# H3 register map
Vendor: Allwinner; Series: H3; File version: 0.1
CPU: 0, little endian, MPU, no FPU, 0 interrupt priority bits
Registers are 32-bit, read-write, reset 0x0 unless marked. A register's access mark holds for its fields unless they carry their own. Offsets are from the block's base; [hi:lo] are bit positions; {n}, {i} and the like mark numbered series; 'fields as' and 'values as' point back to an identical list.

## CCU
Base 0x01C20000
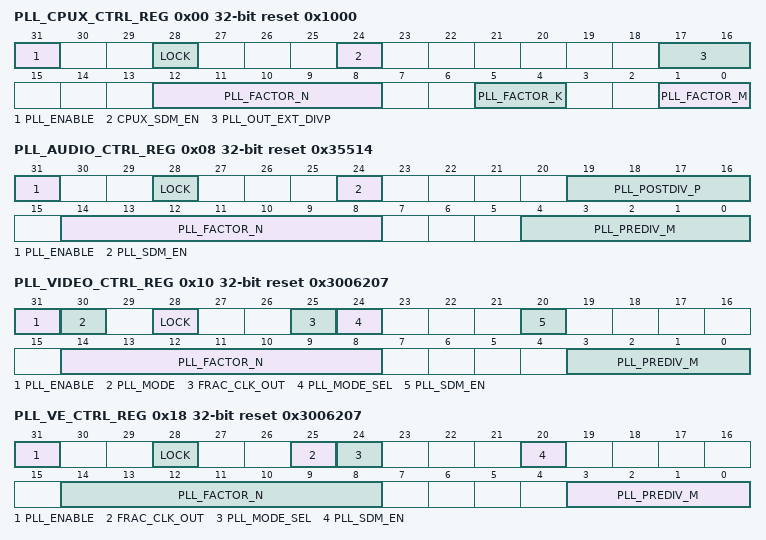
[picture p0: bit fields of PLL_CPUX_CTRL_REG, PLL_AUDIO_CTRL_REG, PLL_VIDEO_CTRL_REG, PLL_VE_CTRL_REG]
0x00 PLL_CPUX_CTRL_REG reset 0x1000 — PLL_CPUX Control Register
  [31] PLL_ENABLE — 0: Disable 1: Enable The PLL Output= (24MHz*N*K)/(M*P). The PLL output is for the CPUX Clock. Note: The PLL output clock must be in the range of 200MHz~2.6GHz. Its default is 408MHz.
    0=Disable; 1=Enable The PLL Output= (24MHz*N*K)/(M*P). The PLL output is for the CPUX Clock. Note: The PLL output clock must be in the range of 200MHz~2.6GHz. Its default is 408MHz.
  [28] LOCK ro — 0: Unlocked 1: Locked (It indicates that the PLL has been stable.)
    0=Unlocked; 1=Locked (It indicates that the PLL has been stable.)
  [24] CPUX_SDM_EN — 0: Disable 1: Enable
    0=Disable; 1=Enable
  [17:16] PLL_OUT_EXT_DIVP — PLL Output external divider P 00: /1 01: /2 10: /4 11: / Note:The P factor only use in the condition that PLL output less than 288 MHz.
    0=_slash_1 (/1); 1=_slash_2 (/2); 2=_slash_4 (/4); 3=_slash_ (/ Note:The P factor only use in the condition that PLL output less than 288 MHz.)
  [12:8] PLL_FACTOR_N — PLL Factor N. Factor=0, N=1 Factor=1, N=2 Factor=2, N=3 ... Factor=31, N=32
  [5:4] PLL_FACTOR_K — PLL Factor K.(K=Factor + 1 ) The range is from 1 to 4.
  [1:0] PLL_FACTOR_M — PLL Factor M. (M=Factor + 1) The range is from 1 to 4.
0x08 PLL_AUDIO_CTRL_REG reset 0x35514 — PLL_AUDIO Control Register
  [31] PLL_ENABLE — 0: Disable 1: Enable. The PLL is for Audio. PLL _AUDIO = (24MHz*N)/(M*P) PLL_AUDIO(8X)= (24MHz*N*2)/M PLL_AUDIO(4X)=PLL_AUDIO(8X)/2 PLL_AUDIO(2X)=PLL_AUDIO(4X)/2 The PLL output clock must be in the range of 20MHz~200MHz. Its default is 24.571MHz.
    0=Disable; 1=Enable. The PLL is for Audio. PLL _AUDIO = (24MHz*N)/(M*P) PLL_AUDIO(8X)= (24MHz*N*2)/M PLL_AUDIO(4X)=PLL_AUDIO(8X)/2 PLL_AUDIO(2X)=PLL_AUDIO(4X)/2 The PLL output clock must be in the range of 20MHz~200MHz. Its default is 24.571MHz.
  [28] LOCK ro — 0: Unlocked 1: Locked (It indicates that the PLL has been stable.)
    values as PLL_CPUX_CTRL_REG.LOCK
  [24] PLL_SDM_EN — 0: Disable 1: Enable In this case, the PLL_FACTOR_N only low 4 bits are valid (N: The range is from 1 to 16).
    0=Disable; 1=Enable In this case, the PLL_FACTOR_N only low 4 bits are valid (N: The range is from 1 to 16)
  [19:16] PLL_POSTDIV_P — Post-div factor (P= Factor+1) The range is from 1 to 16.
  [14:8] PLL_FACTOR_N — PLL Factor N. Factor=0, N=1 Factor=1, N=2 ... Factor=127, N=128
  [4:0] PLL_PREDIV_M — PLL Pre-div Factor(M = Factor+1). The range is from 1 to 32.
0x10 PLL_VIDEO_CTRL_REG reset 0x3006207 — PLL_VIDEO Control Register
  [31] PLL_ENABLE — 0: Disable 1: Enable In the integer mode,the PLL Output = (24MHz*N)/M. In the fractional mode, the PLL Output is select by bit 25. Note: In the Clock Control Module, PLL(1X) Output=PLL while PLL(2X) Output=PLL * 2. The PLL output clock must be in the range of 30MHz~600MHz. Its default is 297MHz.
    0=Disable; 1=Enable In the integer mode,the PLL Output = (24MHz*N)/M. In the fractional mode, the PLL Output is select by bit 25. Note: In the Clock Control Module, PLL(1X) Output=PLL while PLL(2X) Output=PLL * 2. The PLL output clock must be in the range of 30MHz~600MHz. Its default is 297MHz.
  [30] PLL_MODE — 0: Manual Mode 1: Auto Mode (Controlled by DE)
    0=Manual Mode; 1=Auto Mode (Controlled by DE)
  [28] LOCK ro — 0: Unlocked 1: Locked (It indicates that the PLL has been stable.)
    values as PLL_CPUX_CTRL_REG.LOCK
  [25] FRAC_CLK_OUT — PLL clock output when PLL_MODE_SEL=0(PLL_PREDIV_M factor must be set to 0); No meaning when PLL_MODE_SEL =1. 0: PLL Output=270MHz 1: PLL Output =297MHz
    0=PLL_Output_equals_270MHz (PLL Output=270MHz); 1=PLL Output =297MHz
  [24] PLL_MODE_SEL — 0: Fractional Mode 1: Integer Mode Note: When in Fractional mode, the Per Divider M should be set to 0.
    0=Fractional Mode; 1=Integer Mode Note: When in Fractional mode, the Per Divider M should be set to 0
  [20] PLL_SDM_EN — 0: Disable 1: Enable
    0=Disable; 1=Enable
  [14:8] PLL_FACTOR_N — PLL Factor N. Factor=0, N=1 Factor=1, N=2 Factor=2, N=3 ... Factor=127, N=128
  [3:0] PLL_PREDIV_M — PLL Pre-div Factor(M = Factor+1). The range is from 1 to 16.
0x18 PLL_VE_CTRL_REG reset 0x3006207 — PLL_VE Control Register
  [31] PLL_ENABLE — 0: Disable 1: Enable In the integer mode, The PLL Output = (24MHz*N)/M. In the fractional mode, the PLL Output is select by bit 25. Note: The PLL output clock must be in the range of 30MHz~600MHz. Its default is 297MHz.
    0=Disable; 1=Enable In the integer mode, The PLL Output = (24MHz*N)/M. In the fractional mode, the PLL Output is select by bit 25. Note: The PLL output clock must be in the range of 30MHz~600MHz. Its default is 297MHz.
  [28] LOCK ro — 0: Unlocked 1: Locked (It indicates that the PLL has been stable.)
    values as PLL_CPUX_CTRL_REG.LOCK
  [25] FRAC_CLK_OUT — PLL clock output when PLL_MODE_SEL=0(PLL_PREDIV_M factor must be set to 0); No meaning when PLL_MODE_SEL =1. 0: PLL Output=270MHz 1: PLL Output =297MHz
    values as PLL_VIDEO_CTRL_REG.FRAC_CLK_OUT
  [24] PLL_MODE_SEL — 0: Fractional Mode 1: Integer Mode Note: When in Fractional mode, the Per Divider M should be set to 0.
    values as PLL_VIDEO_CTRL_REG.PLL_MODE_SEL
  [20] PLL_SDM_EN — 0: Disable 1: Enable
    0=Disable; 1=Enable
  [14:8] PLL_FACTOR_N — PLL Factor N. Factor=0, N=1 Factor=1, N=2 Factor=2, N=3 ... Factor=31, N=32 ... Factor=127, N=128
  [3:0] PLL_PREDIV_M — PLL Pre Divider (M = Factor+1). The range is from 1 to 16.
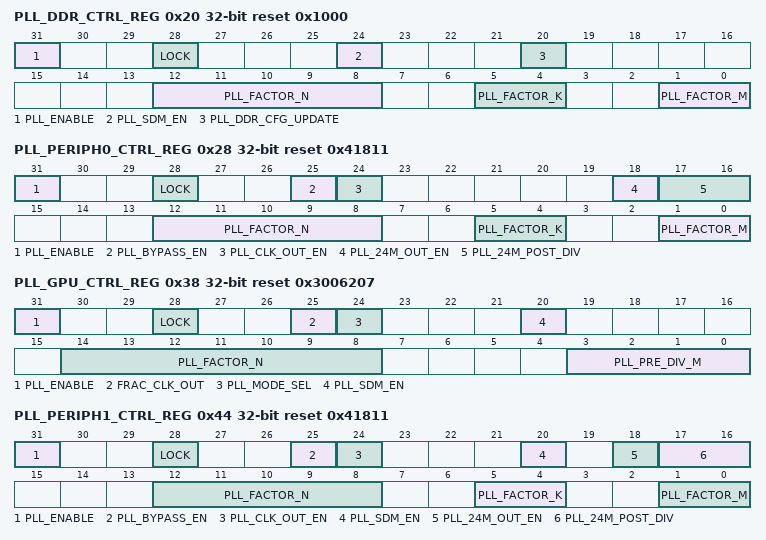
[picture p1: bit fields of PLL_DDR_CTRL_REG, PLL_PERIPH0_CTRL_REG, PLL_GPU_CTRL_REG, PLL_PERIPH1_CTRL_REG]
0x20 PLL_DDR_CTRL_REG reset 0x1000 — PLL_DDR Control Register
  [31] PLL_ENABLE — 0: Disable 1: Enable Set bit20 to validate the PLL after this bit is set to 1. The PLL Output = (24MHz*N*K)/M. Note: the PLL output clock must be in the range of 200MHz~2.6GHz. Its default is 408MHz.
    0=Disable; 1=Enable Set bit20 to validate the PLL after this bit is set to 1. The PLL Output = (24MHz*N*K)/M. Note: the PLL output clock must be in the range of 200MHz~2.6GHz. Its default is 408MHz.
  [28] LOCK ro — 0: Unlocked 1: Locked (It indicates that the PLL has been stable.)
    values as PLL_CPUX_CTRL_REG.LOCK
  [24] PLL_SDM_EN — 0: Disable 1: Enable
    0=Disable; 1=Enable
  [20] PLL_DDR_CFG_UPDATE — PLL_DDR Configuration Update. When PLL_DDR has been changed, this bit should be set to 1 to validate the PLL, otherwise the change would be invalid. And this bit would be cleared automatically after the PLL change is valid. 0: No effect 1: Validating the PLL_DDR
    0=No_effect; 1=Validating the PLL_DDR
  [12:8] PLL_FACTOR_N — PLL Factor N. Factor=0, N=1 Factor=1, N=2 Factor=2, N=3 ... Factor=31, N=32
  [5:4] PLL_FACTOR_K — PLL Factor K.(K=Factor + 1 ) The range is from 1 to 4.
  [1:0] PLL_FACTOR_M — PLL Factor M.(M = Factor + 1 ) The range is from 1 to 4.
0x28 PLL_PERIPH0_CTRL_REG reset 0x41811 — PLL_PERIPH0 Control Register
  [31] PLL_ENABLE — 0: Disable 1: Enable The PLL Output = 24MHz*N*K/2. Note: The PLL Output should be fixed to 600MHz, it is not recommended to vary this value arbitrarily. In the Clock Control Module, PLL(2X) output= PLL*2 = 24MHz*N*K. The PLL output clock must be in the range of 200MHz~1.8GHz. Its default is 600MHz.
    0=Disable; 1=Enable The PLL Output = 24MHz*N*K/2. Note: The PLL Output should be fixed to 600MHz, it is not recommended to vary this value arbitrarily. In the Clock Control Module, PLL(2X) output= PLL*2 = 24MHz*N*K. The PLL output clock must be in the range of 200MHz~1.8GHz. Its default is 600MHz.
  [28] LOCK ro — 0: Unlocked 1: Locked (It indicates that the PLL has been stable.)
    values as PLL_CPUX_CTRL_REG.LOCK
  [25] PLL_BYPASS_EN — PLL Output Bypass Enable. 0: Disable 1: Enable If the bypass is enabled, the PLL output is 24MHz.
    0=Disable; 1=Enable If the bypass is enabled, the PLL output is 24MHz
  [24] PLL_CLK_OUT_EN — PLL clock output enable. 0: Disable 1: Enable
    0=Disable; 1=Enable
  [18] PLL_24M_OUT_EN — PLL 24MHz Output Enable. 0: Disable 1: Enable When 25MHz crystal used, this PLL can output 24MHz.
    0=Disable; 1=Enable When 25MHz crystal used, this PLL can output 24MHz
  [17:16] PLL_24M_POST_DIV — PLL 24M Output Clock Post Divider (When 25MHz crystal used). 1/2/3/4.
  [12:8] PLL_FACTOR_N — PLL Factor N. Factor=0, N=1 Factor=1, N=2 Factor=2, N=3 ... Factor=31, N=32
  [5:4] PLL_FACTOR_K — PLL Factor K.(K=Factor + 1 ) The range is from 1 to 4.
  [1:0] PLL_FACTOR_M — PLL Factor M (M = Factor + 1) is only valid in plltest debug. The PLL_PERIPH back door clock output =24MHz*N*K/M. The range is from 1 to 4.
0x38 PLL_GPU_CTRL_REG reset 0x3006207 — PLL_GPU Control Register
  [31] PLL_ENABLE — 0: Disable 1: Enable In the integer mode, The PLL_GPU Output= (24MHz*N)/M. In the fractional mode, the PLL_GPU Output is select by bit 25. Note: The PLL output clock must be in the range of 30MHz~600MHz. Its default is 297MHz.
    0=Disable; 1=Enable In the integer mode, The PLL_GPU Output= (24MHz*N)/M. In the fractional mode, the PLL_GPU Output is select by bit 25. Note: The PLL output clock must be in the range of 30MHz~600MHz. Its default is 297MHz.
  [28] LOCK ro — 0: Unlocked 1: Locked (It indicates that the PLL has been stable.)
    values as PLL_CPUX_CTRL_REG.LOCK
  [25] FRAC_CLK_OUT — PLL clock output when PLL_MODE_SEL=0(PLL_PREDIV_M factor must be set to 0); no meaning when PLL_MODE_SEL =1. 0: PLL Output=270MHz 1: PLL Output=297MHz
    0=PLL_Output_equals_270MHz (PLL Output=270MHz); 1=PLL_Output_equals_297MHz (PLL Output=297MHz)
  [24] PLL_MODE_SEL — 0: Fractional Mode. 1: Integer Mode Note: When in Fractional mode, the Per Divider M should be set to 0.
    values as PLL_VIDEO_CTRL_REG.PLL_MODE_SEL
  [20] PLL_SDM_EN — 0: Disable 1: Enable
    0=Disable; 1=Enable
  [14:8] PLL_FACTOR_N — PLL Factor N. Factor=0, N=1 Factor=1, N=2 Factor=2, N=3 ... Factor=127, N=128
  [3:0] PLL_PRE_DIV_M — PLL Pre Divider (M = Factor+1). The range is from 1 to 16.
0x44 PLL_PERIPH1_CTRL_REG reset 0x41811
  [31] PLL_ENABLE — 0: Disable 1: Enable The PLL Output = 24MHz*N*K/2. Note: The PLL Output should be fixed to 600MHz, it is not recommended to vary this value arbitrarily. In the Clock Control Module, PLL(2X) output= PLL*2 = 24MHz*N*K. The PLL output clock must be in the range of 200MHz~1.8GHz. Its default is 600MHz.
    values as PLL_PERIPH0_CTRL_REG.PLL_ENABLE
  [28] LOCK ro — 0: Unlocked 1: Locked (It indicates that the PLL has been stable.)
    values as PLL_CPUX_CTRL_REG.LOCK
  [25] PLL_BYPASS_EN — PLL Output Bypass Enable. 0: Disable 1: Enable If the bypass is enabled, the PLL output is 24MHz.
    values as PLL_PERIPH0_CTRL_REG.PLL_BYPASS_EN
  [24] PLL_CLK_OUT_EN — PLL clock output enable. 0: Disable 1: Enable
    0=Disable; 1=Enable
  [20] PLL_SDM_EN — 0: Disable 1: Enable
    0=Disable; 1=Enable
  [18] PLL_24M_OUT_EN — PLL 24MHz Output Enable. 0: Disable 1: Enable When 25MHz crystal used, this PLL can output 24MHz.
    values as PLL_PERIPH0_CTRL_REG.PLL_24M_OUT_EN
  [17:16] PLL_24M_POST_DIV — PLL 24M Output Clock Post Divider (When 25MHz crystal used). 1/2/3/4.
  [12:8] PLL_FACTOR_N — PLL Factor N. Factor=0, N=1 Factor=1, N=2 Factor=2, N=3 ... Factor=31, N=32
  [5:4] PLL_FACTOR_K — PLL Factor K.(K=Factor + 1 ) The range is from 1 to 4.
  [1:0] PLL_FACTOR_M — PLL Factor M (M = Factor + 1) is only valid in plltest debug. The PLL_PERIPH back door clock output =24MHz*N*K/M. The range is from 1 to 4.
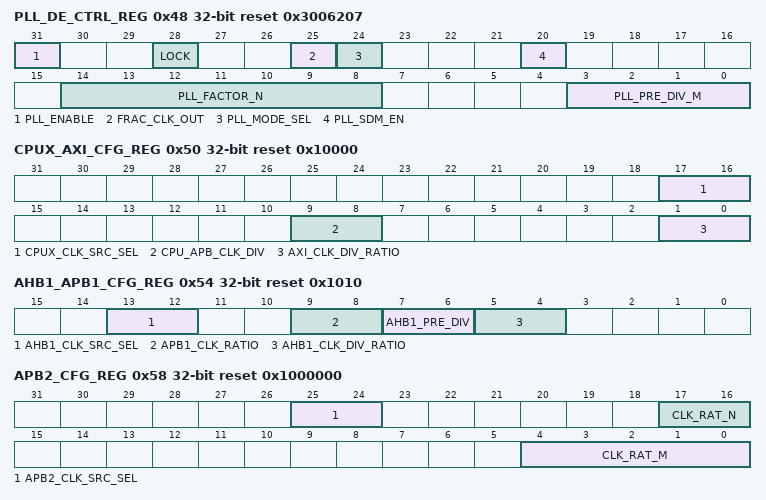
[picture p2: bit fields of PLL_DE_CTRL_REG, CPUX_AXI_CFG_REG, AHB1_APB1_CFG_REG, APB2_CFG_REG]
0x48 PLL_DE_CTRL_REG reset 0x3006207 — PLL_DE Control Register
  [31] PLL_ENABLE — 0: Disable 1: Enable In the integer mode, The PLL Output= (24MHz*N)/M. In the fractional mode, the PLL Output is select by bit 25. Its default is 297MHz.
    0=Disable; 1=Enable In the integer mode, The PLL Output= (24MHz*N)/M. In the fractional mode, the PLL Output is select by bit 25. Its default is 297MHz.
  [28] LOCK ro — 0: Unlocked 1: Locked (It indicates that the PLL has been stable.)
    values as PLL_CPUX_CTRL_REG.LOCK
  [25] FRAC_CLK_OUT — PLL clock output when PLL_MODE_SEL=0(PLL_PREDIV_M factor must be set to 0); no meaning when PLL_MODE_SEL =1. 0: PLL Output=270MHz 1: PLL Output =297MHz
    values as PLL_VIDEO_CTRL_REG.FRAC_CLK_OUT
  [24] PLL_MODE_SEL — 0: Fractional Mode 1: Integer Mode Note: When in Fractional mode, the Pre Divider M should be set to 0.
    0=Fractional Mode; 1=Integer Mode Note: When in Fractional mode, the Pre Divider M should be set to 0
  [20] PLL_SDM_EN — 0: Disable 1: Enable
    0=Disable; 1=Enable
  [14:8] PLL_FACTOR_N — PLL Factor N. Factor=0, N=1 Factor=1, N=2 Factor=2, N=3 ... Factor=0x7F, N=128
  [3:0] PLL_PRE_DIV_M — PLL Per Divider (M = Factor+1). The range is from 1 to 16.
0x50 CPUX_AXI_CFG_REG reset 0x10000 — CPUX/AXI Configuration Register
  [17:16] CPUX_CLK_SRC_SEL — CPUX Clock Source Select. CPUX Clock = Clock Source 00: LOSC 01: OSC24M 1X: PLL_CPUX If the clock source is changed, at most to wait for 8 present running clock cycles.
    0=LOSC; 1=OSC24M; 2=PLL_CPUX (PLL_CPUX If the clock source is changed, at most to wait for 8 present running clock cycles.)
  [9:8] CPU_APB_CLK_DIV — 00: /1 01: /2 1x: /4 Note: System APB clock source is CPU clock source.
    0=_slash_1 (/1); 1=_slash_2 (/2); 2=_slash_4 (/4 Note: System APB clock source is CPU clock source.)
  [1:0] AXI_CLK_DIV_RATIO — AXI Clock Divide Ratio. AXI Clock source is CPU clock source. 00: /1 01: /2 10: /3 11: /4
    {v}=_slash_{v+1} (/{v+1}) (v=0..3)
0x54 AHB1_APB1_CFG_REG reset 0x1010 — AHB1/APB1 Configuration Register
  [13:12] AHB1_CLK_SRC_SEL — 00: LOSC 01: OSC24M 10: AXI 11: PLL_PERIPH0/ AHB1_PRE_DIV
    0=LOSC; 1=OSC24M; 2=AXI; 3=PLL_PERIPH0_slash_ (PLL_PERIPH0/ AHB1_PRE_DIV)
  [9:8] APB1_CLK_RATIO — APB1 Clock Divide Ratio. APB1 clock source is AHB1 clock. 00: /2 01: /2 10: /4 11: /8
  [7:6] AHB1_PRE_DIV — AHB1 Clock Pre Divide Ratio 00: /1 01: /2 10: /3 11: /4
    {v}=_slash_{v+1} (/{v+1}) (v=0..3)
  [5:4] AHB1_CLK_DIV_RATIO — AHB1 Clock Divide Ratio. 00: /1 01: /2 10: /4 11: /8
    0=_slash_1 (/1); 1=_slash_2 (/2); 2=_slash_4 (/4); 3=_slash_8 (/8)
0x58 APB2_CFG_REG reset 0x1000000
  [25:24] APB2_CLK_SRC_SEL — APB2 Clock Source Select 00: LOSC 01: OSC24M 1X: PLL_PERIPH0 This clock is used for some special module apbclk(UART TWI). Because these modules need special clock rate even if the apb1clk changed.
    0=LOSC; 1=OSC24M; 2=PLL_PERIPH0 (PLL_PERIPH0 This clock is used for some special module apbclk(UART TWI). Because these modules need special clock rate even if the apb1clk changed.)
  [17:16] CLK_RAT_N — Clock Pre Divide Ratio (n) The select clock source is pre-divided by 2^n. The divider is 1/2/4/8.
  [4:0] CLK_RAT_M — Clock Divide Ratio (m) The Pre Divide clock is divided by (m+1). The divider M is from 1 to 32.
0x5C AHB2_CFG_REG — AHB2 Configuration Register
  [1:0] AHB2_CLK_CFG — 00: AHB1 Clock 01: PLL_PERIPH0 / 2 1X: / EMAC ,USBHCI1/2/3 default clock source is AHB2 Clock.
    0=AHB1 (AHB1 Clock); 1=PLL_PERIPH0 (PLL_PERIPH0 / 2); 2=_slash_ (/ EMAC ,USBHCI1/2/3 default clock source is AHB2 Clock.)
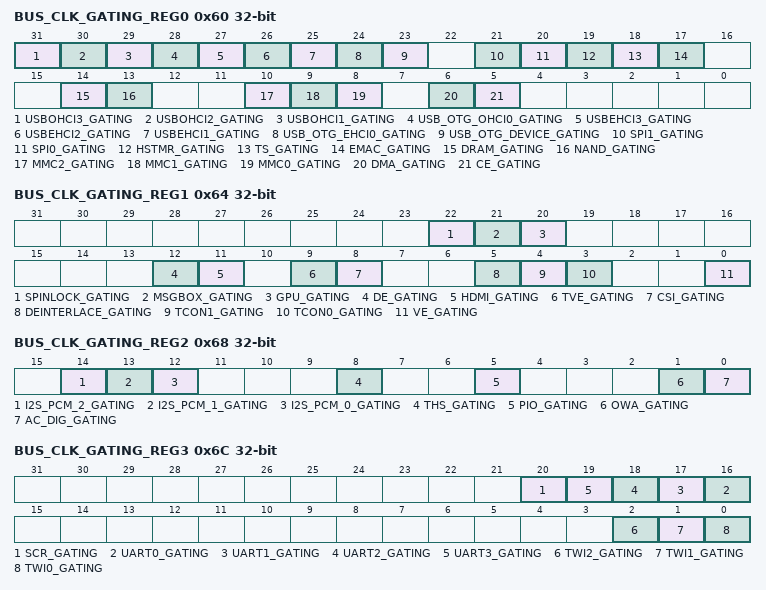
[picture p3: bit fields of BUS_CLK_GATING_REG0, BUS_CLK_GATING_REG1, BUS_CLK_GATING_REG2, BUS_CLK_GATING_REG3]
0x60 BUS_CLK_GATING_REG0 — Bus Clock Gating Register 0
  [all] fields
    0=Mask; 1=Pass
  [31] USBOHCI3_GATING — USBOHCI3_GATING. Gating Clock for USB OHCI3 0: Mask 1: Pass
  [30] USBOHCI2_GATING — USBOHCI2_GATING. Gating Clock for USB OHCI2 0: Mask 1: Pass
  [29] USBOHCI1_GATING — USBOHCI1_GATING. Gating Clock for USB OHCI1 0: Mask 1: Pass
  [28] USB_OTG_OHCI0_GATING — USB OTG_OHCI0_GATING. Gating Clock for USB OTG_OHCI0 0: Mask 1: Pass
  [27] USBEHCI3_GATING — USBEHCI3_GATING. Gating Clock For USB EHCI3 0: Mask 1: Pass
  [26] USBEHCI2_GATING — USBEHCI2_GATING. Gating Clock For USB EHCI2 0: Mask 1: Pass
  [25] USBEHCI1_GATING — USBEHCI1_GATING. Gating Clock For USB EHCI1 0: Mask 1: Pass
  [24] USB_OTG_EHCI0_GATING — USB OTG_EHCI0_GATING. Gating Clock For USB OTG_EHCI0 0: Mask 1: Pass
  [23] USB_OTG_DEVICE_GATING — USB OTG_Device_GATING. Gating Clock For USB OTG_Device 0: Mask 1: Pass
  [21] SPI1_GATING — SPI1_GATING. Gating Clock For SPI1 0: Mask 1: Pass
  [20] SPI0_GATING — SPI0_GATING. Gating Clock For SPI0 0: Mask 1: Pass
  [19] HSTMR_GATING — HSTMR_GATING. Gating Clock For High Speed Timer 0: Mask 1: Pass
  [18] TS_GATING — TS_GATING. Gating Clock For TS 0: Mask 1: Pass
  [17] EMAC_GATING — EMAC_GATING. Gating Clock For EMAC 0: Mask 1: Pass
  [14] DRAM_GATING — DRAM_GATING. Gating Clock For DRAM 0: Mask 1: Pass
  [13] NAND_GATING — NAND_GATING. Gating Clock For NAND 0: Mask 1: Pass
  [10] MMC2_GATING — MMC2_GATING. Gating Clock For MMC2 0: Mask 1: Pass
  [9] MMC1_GATING — MMC1_GATING. Gating Clock For MMC1 0: Mask 1: Pass
  [8] MMC0_GATING — MMC0_GATING. Gating Clock For MMC0 0: Mask 1: Pass
  [6] DMA_GATING — DMA_GATING. Gating Clock For DMA 0: Mask 1: Pass
  [5] CE_GATING — CE_GATING. Gating Clock For CE. 0: Mask 1: Pass
0x64 BUS_CLK_GATING_REG1 — Bus Clock Gating Register 1
  [all] fields
    0=Mask; 1=Pass
  [22] SPINLOCK_GATING — 0: Mask 1: Pass.
  [21] MSGBOX_GATING — 0: Mask 1: Pass.
  [20] GPU_GATING — 0: Mask 1: Pass.
  [12] DE_GATING — 0: Mask 1: Pass.
  [11] HDMI_GATING — 0: Mask 1: Pass.
  [9] TVE_GATING — Gating Clock For TVE 0: Mask 1: Pass.
  [8] CSI_GATING — 0: Mask 1: Pass.
  [5] DEINTERLACE_GATING — Gating Clock For DEINTERLACE 0: Mask 1: Pass
  [4] TCON1_GATING — Gating Clock For TCON1 0: Mask 1: Pass.
  [3] TCON0_GATING — Gating Clock For TCON0 0: Mask 1: Pass.
  [0] VE_GATING — Gating Clock For VE 0: Mask 1: Pass.
0x68 BUS_CLK_GATING_REG2 — Bus Clock Gating Register 2
  [all] fields
    0=Mask; 1=Pass
  [14] I2S_PCM_2_GATING — Gating Clock For I2S/PCM 2 0: Mask 1: Pass.
  [13] I2S_PCM_1_GATING — Gating Clock For I2S/PCM 1 0: Mask 1: Pass.
  [12] I2S_PCM_0_GATING — Gating Clock For I2S/PCM 0 0: Mask 1: Pass.
  [8] THS_GATING — Gating Clock For THS 0: Mask 1: Pass
  [5] PIO_GATING — Gating Clock For PIO 0: Mask 1: Pass.
  [1] OWA_GATING — Gating Clock For OWA 0: Mask 1: Pass.
  [0] AC_DIG_GATING — Gating Clock For AC Digital 0: Mask 1: Pass
0x6C BUS_CLK_GATING_REG3 — Bus Clock Gating Register 3
  [all] fields
    0=Mask; 1=Pass
  [20] SCR_GATING — Gating Clock For SCR 0: Mask 1: Pass
  [n+16] UART{n}_GATING (n=0..3) — Gating Clock For UART{n} 0: Mask 1: Pass.
  [2] TWI2_GATING — Gating Clock For TWI2 0: Mask 1: Pass.
  [1] TWI1_GATING — Gating Clock For TWI1 0: Mask 1: Pass.
  [0] TWI0_GATING — Gating Clock For TWI0 0: Mask 1: Pass.
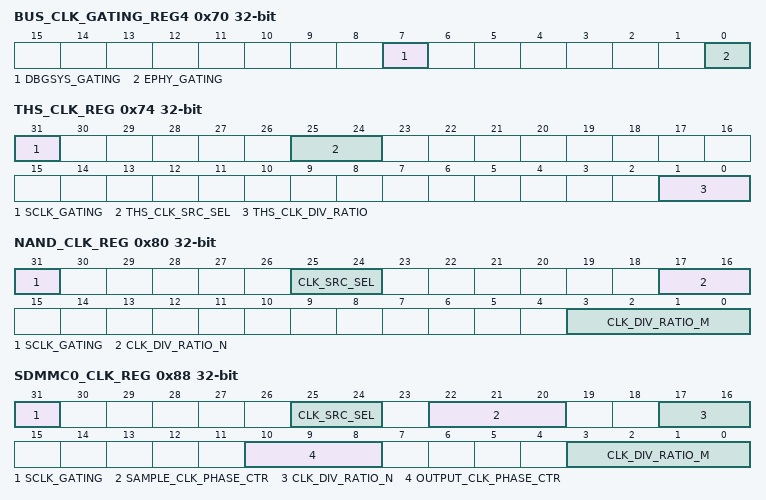
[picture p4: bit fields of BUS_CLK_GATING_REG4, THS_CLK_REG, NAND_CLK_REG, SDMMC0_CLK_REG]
0x70 BUS_CLK_GATING_REG4 — Bus Clock Gating Register4
  [7] DBGSYS_GATING — Gating Clock For DBGSYS 0: Mask 1: Pass
    0=Mask; 1=Pass
  [0] EPHY_GATING — Gating Clock For EPHY 0: Mask 1: Pass
    0=Mask; 1=Pass
0x74 THS_CLK_REG — THS Clock Register
  [31] SCLK_GATING — Gating Special Clock. 0: Clock is OFF 1: Clock is ON This special clock = Clock Source/CLK_DIV_RATIO.
    0=OFF (Clock is OFF); 1=ON (Clock is ON This special clock = Clock Source/CLK_DIV_RATIO.)
  [25:24] THS_CLK_SRC_SEL — Clock Source Select 00: OSC24M 01: / 10: / 11: /
    0=OSC24M
  [1:0] THS_CLK_DIV_RATIO — THS clock divide ratio. 00: /1 01: /2 10: /4 11: /6
    0=_slash_1 (/1); 1=_slash_2 (/2); 2=_slash_4 (/4); 3=_slash_6 (/6)
0x80 NAND_CLK_REG — NAND Clock Register
  [31] SCLK_GATING — Gating Special Clock(Max Clock = 200MHz) 0: Clock is OFF 1: Clock is ON. SCLK = Clock Source/Divider N/Divider M.
    0=OFF (Clock is OFF); 1=ON (Clock is ON. SCLK = Clock Source/Divider N/Divider M.)
  [25:24] CLK_SRC_SEL — Clock Source Select 00: OSC24M 01: PLL_PERIPH0 10: PLL_PERIPH1 11: /
    0=OSC24M; 1=PLL_PERIPH0; 2=PLL_PERIPH1
  [17:16] CLK_DIV_RATIO_N — Clock Pre Divide Ratio (n) 00: /1 01: /2 10: /4 11: /8.
    0=_slash_1 (/1); 1=_slash_2 (/2); 2=_slash_4 (/4); 3=_slash_8 (/8.)
  [3:0] CLK_DIV_RATIO_M — Clock Divide Ratio (m) The pre-divided clock is divided by (m+1). The divider M is from 1 to 16.
0x88 SDMMC0_CLK_REG — SDMMC0 Clock Register
  [31] SCLK_GATING — Gating Special Clock(Max Clock = 200MHz) 0: Clock is OFF 1: Clock is ON. SCLK = Clock Source/Divider N/Divider M.
    values as NAND_CLK_REG.SCLK_GATING
  [25:24] CLK_SRC_SEL — Clock Source Select 00: OSC24M 01: PLL_PERIPH0 10: PLL_PERIPH1 11: /
    0=OSC24M; 1=PLL_PERIPH0; 2=PLL_PERIPH1
  [22:20] SAMPLE_CLK_PHASE_CTR — Sample Clock Phase Control. The sample clock phase delay is based on the number of source clock that is from 0 to 7.
  [17:16] CLK_DIV_RATIO_N — Clock Pre Divide Ratio (n) 00: /1 01: /2 10: /4 11: /8.
    values as NAND_CLK_REG.CLK_DIV_RATIO_N
  [10:8] OUTPUT_CLK_PHASE_CTR — Output Clock Phase Control. The output clock phase delay is based on the number of source clock that is from 0 to 7.
  [3:0] CLK_DIV_RATIO_M — Clock Divide Ratio (m) The pre-divided clock is divided by (m+1). The divider M is from 1 to 16.
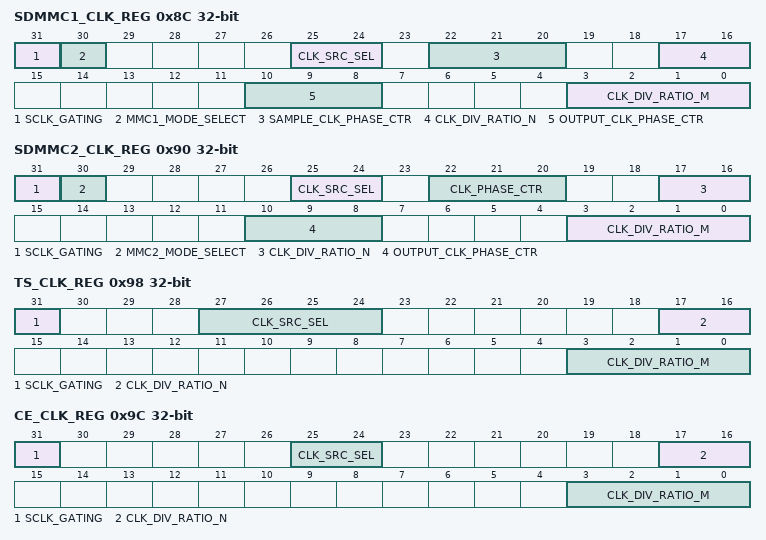
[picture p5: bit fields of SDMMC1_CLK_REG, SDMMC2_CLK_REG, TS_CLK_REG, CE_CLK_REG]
0x8C SDMMC1_CLK_REG — SDMMC1 Clock Register
  [31] SCLK_GATING — Gating Special Clock(Max Clock = 200MHz) 0: Clock is OFF 1: Clock is ON. If SDMMC1 is in old mode, SCLK = Clock Source/Divider N/Divider M. If SDMMC1 is in new mode, SCLK= Clock Source/Divider N/Divider M/2.
    0=OFF (Clock is OFF); 1=ON (Clock is ON. If SDMMC1 is in old mode, SCLK = Clock Source/Divider N/Divider M. If SDMMC1 is in new mode, SCLK= Clock Source/Divider N/Divider M/2.)
  [30] MMC1_MODE_SELECT — 0: Old Mode 1: New Mode.
    0=Old (Old Mode); 1=New (New Mode.)
  [25:24] CLK_SRC_SEL — Clock Source Select 00: OSC24M 01: PLL_PERIPH0 10: PLL_PERIPH1 11: /
    0=OSC24M; 1=PLL_PERIPH0; 2=PLL_PERIPH1
  [22:20] SAMPLE_CLK_PHASE_CTR — Sample Clock Phase Control. The sample clock phase delay is based on the number of source clock that is from 0 to 7.
  [17:16] CLK_DIV_RATIO_N — Clock Pre-Divide Ratio (n) 00: /1 01: /2 10: /4 11: /8.
    values as NAND_CLK_REG.CLK_DIV_RATIO_N
  [10:8] OUTPUT_CLK_PHASE_CTR — Output Clock Phase Control. The output clock phase delay is based on the number of source clock that is from 0 to 7.
  [3:0] CLK_DIV_RATIO_M — Clock Divide Ratio (m) The pre-divided clock is divided by (m+1). The divider M is from 1 to 16.
0x90 SDMMC2_CLK_REG — SDMMC2 Clock Register
  [31] SCLK_GATING — Gating Special Clock(Max Clock = 200MHz) 0: Clock is OFF 1: Clock is ON. If SDMMC2 is in old mode, SCLK = Clock Source/Divider N/Divider M. If SDMMC2 is in new mode, SCLK= Clock Source/Divider N/Divider M/2.
    0=OFF (Clock is OFF); 1=ON (Clock is ON. If SDMMC2 is in old mode, SCLK = Clock Source/Divider N/Divider M. If SDMMC2 is in new mode, SCLK= Clock Source/Divider N/Divider M/2.)
  [30] MMC2_MODE_SELECT — 0: Old Mode 1: New Mode.
    0=Old (Old Mode); 1=New (New Mode.)
  [25:24] CLK_SRC_SEL — Clock Source Select 00: OSC24M 01: PLL_PERIPH0 10: PLL_PERIPH1 11: /
    0=OSC24M; 1=PLL_PERIPH0; 2=PLL_PERIPH1
  [22:20] CLK_PHASE_CTR — Sample Clock Phase Control. The sample clock phase delay is based on the number of source clock that is from 0 to 7.
  [17:16] CLK_DIV_RATIO_N — Clock Pre Divide Ratio (n) 00: /1 01: /2 10: /4 11: /8.
    values as NAND_CLK_REG.CLK_DIV_RATIO_N
  [10:8] OUTPUT_CLK_PHASE_CTR — Output Clock Phase Control. The output clock phase delay is based on the number of source clock that is from 0 to 7.
  [3:0] CLK_DIV_RATIO_M — Clock Divide Ratio (m) The pre-divided clock is divided by (m+1). The divider M is from 1 to 16.
0x98 TS_CLK_REG
  [31] SCLK_GATING — Gating Special Clock(Max Clock = 200MHz) 0: Clock is OFF 1: Clock is ON. SCLK = Clock Source/Divider N/Divider M.
    values as NAND_CLK_REG.SCLK_GATING
  [27:24] CLK_SRC_SEL — Clock Source Select 0000: OSC24M 0001: PLL_PERIPH0 Others: /
    0=OSC24M; 1=PLL_PERIPH0 (PLL_PERIPH0 Others: /)
  [17:16] CLK_DIV_RATIO_N — Clock pre-divide ratio (n) The select clock source is pre-divided by 2^n. The divider is 1/2/4/8.
  [3:0] CLK_DIV_RATIO_M — Clock divide ratio (m) The pre-divided clock is divided by (m+1). The divider is from 1 to 16.
0x9C CE_CLK_REG — CE Clock Register
  [31] SCLK_GATING — Gating Special Clock(Max Clock = 400MHz) 0: Clock is OFF 1: Clock is ON. SCLK = Clock Source/Divider N/Divider M.
    values as NAND_CLK_REG.SCLK_GATING
  [25:24] CLK_SRC_SEL — Clock Source Select 00: OSC24M 01: PLL_PERIPH0 10: PLL_PERIPH1 11: /
    0=OSC24M; 1=PLL_PERIPH0; 2=PLL_PERIPH1
  [17:16] CLK_DIV_RATIO_N — Clock Pre Divide Ratio (n) 00: /1 01: /2 10: /4 11: /8.
    values as NAND_CLK_REG.CLK_DIV_RATIO_N
  [3:0] CLK_DIV_RATIO_M — Clock divide ratio (m) The pre-divided clock is divided by (m+1). The divider M is from 1 to 16.
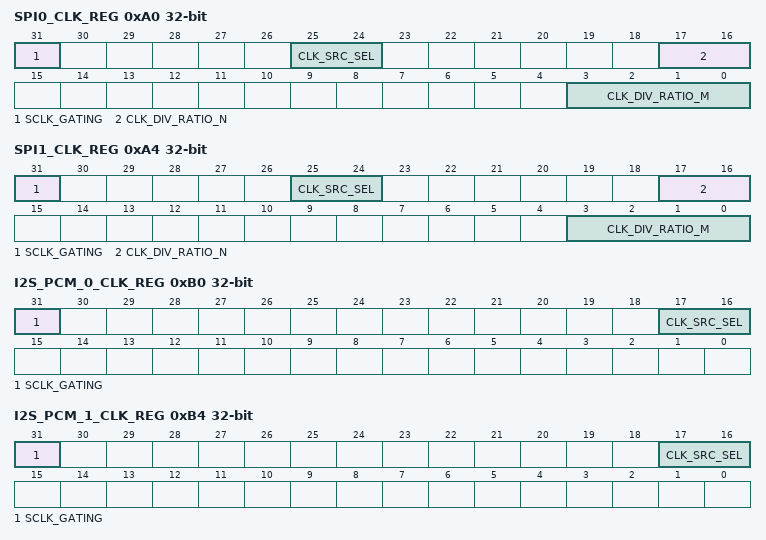
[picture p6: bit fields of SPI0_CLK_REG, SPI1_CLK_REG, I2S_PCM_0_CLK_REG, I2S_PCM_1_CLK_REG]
0xA0 SPI0_CLK_REG — SPI0 Clock Register
  fields as NAND_CLK_REG
0xA4 SPI1_CLK_REG — SPI1 Clock Register
  [31] SCLK_GATING — Gating Special Clock(Max Clock = 200MHz) 0: Clock is OFF 1: Clock is ON. SCLK= Clock Source/Divider N/Divider M.
    0=OFF (Clock is OFF); 1=ON (Clock is ON. SCLK= Clock Source/Divider N/Divider M.)
  [25:24] CLK_SRC_SEL — Clock Source Select 00: OSC24M 01: PLL_PERIPH0 10: PLL_PERIPH1 11: /
    0=OSC24M; 1=PLL_PERIPH0; 2=PLL_PERIPH1
  [17:16] CLK_DIV_RATIO_N — Clock Pre Divide Ratio (n) 00: /1 01: /2 10: /4 11: /8.
    values as NAND_CLK_REG.CLK_DIV_RATIO_N
  [3:0] CLK_DIV_RATIO_M — Clock Divide Ratio (m) The pre-divided clock is divided by (m+1). The divider M is from 1 to 16.
0xB0 I2S_PCM_0_CLK_REG
  [31] SCLK_GATING — Gating Special Clock(Max Clock = 200MHz) 0: Clock is OFF 1: Clock is ON. SCLK= Clock Source PLL_AUDIO/Divider M.
    0=OFF (Clock is OFF); 1=ON (Clock is ON. SCLK= Clock Source PLL_AUDIO/Divider M.)
  [17:16] CLK_SRC_SEL — 00: PLL_AUDIO(8X) 01: PLL_AUDIO(8X)/2 10: PLL_AUDIO(8X)/4 11: PLL_AUDIO
    0=PLL_AUDIO_openingparen_8X_closingparen_ (PLL_AUDIO(8X)); 1=PLL_AUDIO_openingparen_8X_closingparen__slash_2 (PLL_AUDIO(8X)/2); 2=PLL_AUDIO_openingparen_8X_closingparen__slash_4 (PLL_AUDIO(8X)/4); 3=PLL_AUDIO
0xB4 I2S_PCM_1_CLK_REG
  [31] SCLK_GATING — Gating Special Clock(Max Clock = 200MHz) 0: Clock is OFF 1: Clock is ON.
    0=OFF (Clock is OFF); 1=ON (Clock is ON.)
  [17:16] CLK_SRC_SEL — 00: PLL_AUDIO (8X) 01: PLL_AUDIO(8X)/2 10: PLL_AUDIO(8X)/4 11: PLL_AUDIO
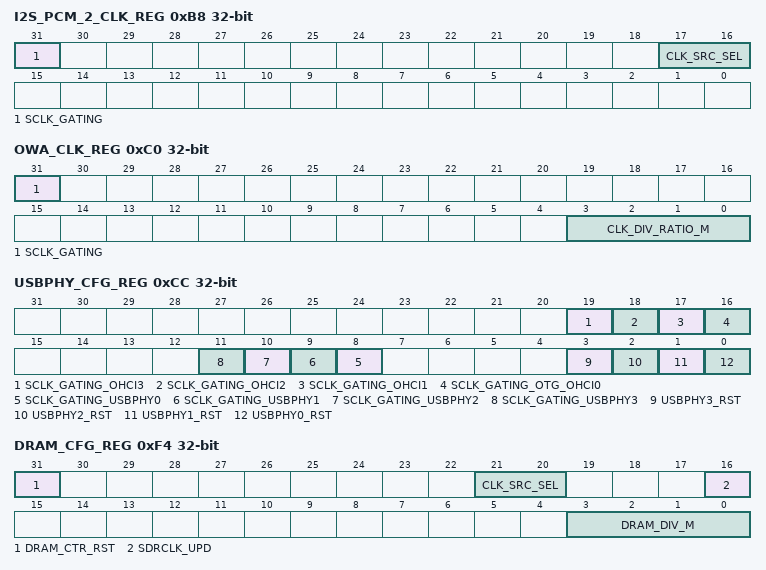
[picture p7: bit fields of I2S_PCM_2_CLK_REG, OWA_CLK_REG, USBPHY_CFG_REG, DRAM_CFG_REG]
0xB8 I2S_PCM_2_CLK_REG
  fields as I2S_PCM_1_CLK_REG
0xC0 OWA_CLK_REG — OWA Clock Register
  [31] SCLK_GATING — Gating Special Clock(Max Clock = 200MHz) 0: Clock is OFF 1: Clock is ON. SCLK= PLL_AUDIO/Divider M.
    0=OFF (Clock is OFF); 1=ON (Clock is ON. SCLK= PLL_AUDIO/Divider M.)
  [3:0] CLK_DIV_RATIO_M — Clock Divide Ratio (m) The pre-divided clock is divided by (m+1). The divider M is from 1 to 16.
0xCC USBPHY_CFG_REG — USBPHY Configuration Register
  [19] SCLK_GATING_OHCI3 — Gating Special Clock For OHCI3 0: Clock is OFF 1: Clock is ON
    0=OFF (Clock is OFF); 1=ON (Clock is ON)
  [18] SCLK_GATING_OHCI2 — Gating Special Clock For OHCI2 0: Clock is OFF 1: Clock is ON
    0=OFF (Clock is OFF); 1=ON (Clock is ON)
  [17] SCLK_GATING_OHCI1 — Gating Special Clock For OHCI1 0: Clock is OFF 1: Clock is ON
    0=OFF (Clock is OFF); 1=ON (Clock is ON)
  [16] SCLK_GATING_OTG_OHCI0 — Gating Special Clock For USB OTG_OHCI0 0: Clock is OFF 1: Clock is ON
    0=OFF (Clock is OFF); 1=ON (Clock is ON)
  [n+8] SCLK_GATING_USBPHY{n} (n=0..3) — Gating Special Clock For USB PHY{n} 0: Clock is OFF 1: Clock is ON
    0=OFF (Clock is OFF); 1=ON (Clock is ON)
  [3] USBPHY3_RST — USB PHY3 Reset Control 0: Assert 1: De-assert
    0=Assert; 1=deassert
  [2] USBPHY2_RST — USB PHY2 Reset Control 0: Assert 1: De-assert.
    0=Assert; 1=deassert
  [1] USBPHY1_RST — USB PHY1 Reset Control 0: Assert 1: De-assert
    0=Assert; 1=deassert
  [0] USBPHY0_RST — USB PHY0 Reset Control 0: Assert 1: De-assert
    0=Assert; 1=deassert
0xF4 DRAM_CFG_REG — DRAM Configuration Register
  [31] DRAM_CTR_RST — DRAM Controller Reset For AHB Clock Domain. 0: Assert 1: De-assert.
    0=Assert; 1=deassert
  [21:20] CLK_SRC_SEL — 00: PLL_DDR 01: PLL_PERIPH0 (2X) Others: /
    0=PLL_DDR; 1=PLL_PERIPH0 (PLL_PERIPH0 (2X) Others: /)
  [16] SDRCLK_UPD — SDRCLK Configuration Update. 0:Invalid 1:Valid. Note: Set this bit will validate Configuration . It will be auto cleared after the Configuration is valid. The DRAMCLK Source is from PLL_DDR.
  [3:0] DRAM_DIV_M — DRAMCLK Divider of Configuration. The clock is divided by (m+1). The divider M should be from 1 to 16.
0xFC MBUS_RST_REG reset 0x80000000 — MBUS Reset Register
  [31] MBUS_RESET — 0: Reset Mbus Domain 1: Assert Mbus Domain.
    0=Reset Mbus Domain; 1=Assert Mbus Domain
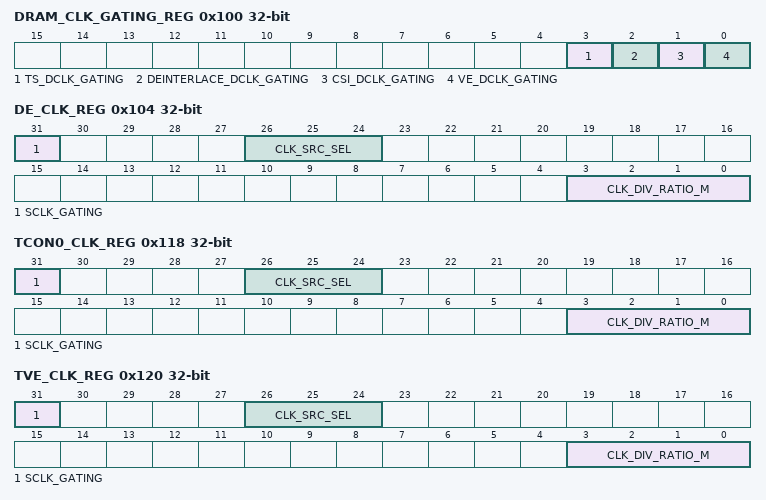
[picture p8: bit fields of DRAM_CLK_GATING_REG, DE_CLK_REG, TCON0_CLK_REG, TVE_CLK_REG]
0x100 DRAM_CLK_GATING_REG — DRAM Clock Gating Register
  [all] fields
    0=Mask; 1=Pass
  [3] TS_DCLK_GATING — Gating DRAM Clock For TS 0: Mask 1: Pass
  [2] DEINTERLACE_DCLK_GATING — Gating DRAM SCLK(1X) For DEINTERLACE 0: Mask 1: Pass
  [1] CSI_DCLK_GATING — Gating DRAM Clock For CSI 0: Mask 1: Pass
  [0] VE_DCLK_GATING — Gating DRAM Clock For VE 0: Mask 1: Pass
0x104 DE_CLK_REG
  [31] SCLK_GATING — Gating Special Clock 0: Clock is OFF 1: Clock is ON This special clock = Clock Source/Divider M.
    0=OFF (Clock is OFF); 1=ON (Clock is ON This special clock = Clock Source/Divider M.)
  [26:24] CLK_SRC_SEL — Clock Source Select 000: PLL_PERIPH0(2X) 001: PLL_DE Others: /
    0=PLL_PERIPH0_openingparen_2X_closingparen_ (PLL_PERIPH0(2X)); 1=PLL_DE (PLL_DE Others: /)
  [3:0] CLK_DIV_RATIO_M — Clock Divide Ratio (m) The pre-divided clock is divided by (m+1). The divider is from 1 to 16.
0x118 TCON0_CLK_REG — TCON0 Clock Register
  [31] SCLK_GATING — Gating Special Clock 0: Clock is OFF 1: Clock is ON.
    0=OFF (Clock is OFF); 1=ON (Clock is ON.)
  [26:24] CLK_SRC_SEL — Clock Source Select 000: PLL_VIDEO Others: /.
    0=PLL_VIDEO (PLL_VIDEO Others: /.)
  [3:0] CLK_DIV_RATIO_M — Clock Divide Ratio (m) The pre-divided clock is divided by (m+1). The divider M is from 1 to 16.
0x120 TVE_CLK_REG — TVE Clock Register
  [31] SCLK_GATING — Gating Special Clock 0: Clock is OFF 1: Clock is ON SCLK= Clock Source/ Divider M.
    0=OFF (Clock is OFF); 1=ON (Clock is ON SCLK= Clock Source/ Divider M.)
  [26:24] CLK_SRC_SEL — Clock Source Select 000: PLL_DE 001: PLL_PERIPH1 Others: /
    0=PLL_DE; 1=PLL_PERIPH1 (PLL_PERIPH1 Others: /)
  [3:0] CLK_DIV_RATIO_M — Clock Divide Ratio (m) The pre-divided clock is divided by (m+1). The divider is from 1 to 16.
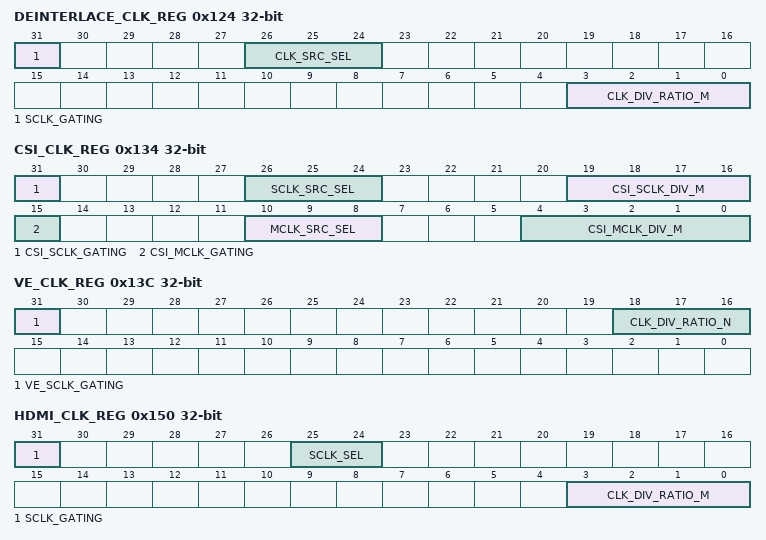
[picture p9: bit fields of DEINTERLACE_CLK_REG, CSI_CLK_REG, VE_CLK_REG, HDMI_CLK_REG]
0x124 DEINTERLACE_CLK_REG — DEINTERLACE Clock Register
  [31] SCLK_GATING — Gating Special Clock 0: Clock is OFF 1: Clock is ON SCLK = Clock Source/ Divider M
    0=OFF (Clock is OFF); 1=ON (Clock is ON SCLK = Clock Source/ Divider M)
  [26:24] CLK_SRC_SEL — Clock Source Select 000: PLL_PERIPH0 001: PLL_PERIPH1 Others: /
    0=PLL_PERIPH0; 1=PLL_PERIPH1 (PLL_PERIPH1 Others: /)
  [3:0] CLK_DIV_RATIO_M — Clock Divide Ratio (m) The pre-divided clock is divided by (m+1). The divider is from 1 to 16.
0x130 CSI_MISC_CLK_REG — CSI_MISC Clock Register
  [31] MIPI_CSI_CFG — 0: Clock is OFF 1: Clock is ON. This clock = OSC24M.
    0=OFF (Clock is OFF); 1=ON (Clock is ON. This clock = OSC24M.)
0x134 CSI_CLK_REG — CSI Clock Register
  [31] CSI_SCLK_GATING — Gating Special Clock 0: Clock is OFF 1: Clock is ON. SCLK= Special Clock Source/CSI_SCLK_DIV_M.
    0=OFF (Clock is OFF); 1=ON (Clock is ON. SCLK= Special Clock Source/CSI_SCLK_DIV_M.)
  [26:24] SCLK_SRC_SEL — Special Clock Source Select 000: PLL_PERIPH0 001: PLL_PERIPH1 Others: /
    0=PLL_PERIPH0; 1=PLL_PERIPH1 (PLL_PERIPH1 Others: /)
  [19:16] CSI_SCLK_DIV_M — CSI Clock Divide Ratio (m) The pre-divided clock is divided by (m+1). The divider M is from 1 to 16.
  [15] CSI_MCLK_GATING — Gating Master Clock 0: Clock is OFF 1: Clock is ON This clock =Master Clock Source/ CSI_MCLK_DIV_M.
    0=OFF (Clock is OFF); 1=ON (Clock is ON This clock =Master Clock Source/ CSI_MCLK_DIV_M.)
  [10:8] MCLK_SRC_SEL — Master Clock Source Select 000: OSC24M 001: PLL_VIDEO 010: PLL_PERIPH1 Others: /
    0=OSC24M; 1=PLL_VIDEO; 2=PLL_PERIPH1 (PLL_PERIPH1 Others: /)
  [4:0] CSI_MCLK_DIV_M — CSI Master Clock Divide Ratio (m) The pre-divided clock is divided by (m+1). The divider is from 1 to 32.
0x13C VE_CLK_REG — VE Clock Register
  [31] VE_SCLK_GATING — Gating Special Clock 0: Clock is OFF 1: Clock is ON. SCLK = PLL_VE /Divider N.
    0=OFF (Clock is OFF); 1=ON (Clock is ON. SCLK = PLL_VE /Divider N.)
  [18:16] CLK_DIV_RATIO_N — Clock Pre Divide Ratio (N) The select clock source is pre-divided by n+1. The divider N is from 1 to 8.
0x140 AC_DIG_CLK_REG — AC Digital Clock Register
  [31] SCLK_1X_GATING — Gating Special Clock 0: Clock is OFF 1: Clock is ON SCLK = PLL_AUDIO Output.
    0=OFF (Clock is OFF); 1=ON (Clock is ON SCLK = PLL_AUDIO Output.)
0x144 AVS_CLK_REG — AVS Clock Register
  [31] SCLK_GATING — Gating Special Clock 0: Clock is OFF 1: Clock is ON. SCLK= OSC24M.
    0=OFF (Clock is OFF); 1=ON (Clock is ON. SCLK= OSC24M.)
0x150 HDMI_CLK_REG — HDMI Clock Register
  [31] SCLK_GATING — Gating Special Clock 0: Clock is OFF 1: Clock is ON. SCLK= Clock Source/ Divider M.
    0=OFF (Clock is OFF); 1=ON (Clock is ON. SCLK= Clock Source/ Divider M.)
  [25:24] SCLK_SEL — Special Clock Source Select 00: PLL_VIDEO Others: /
    0=PLL_VIDEO (PLL_VIDEO Others: /)
  [3:0] CLK_DIV_RATIO_M — Clock Divide Ratio (m) The pre-divided clock is divided by (m+1). The divider M is from 1 to 16.
0x154 HDMI_SLOW_CLK_REG — HDMI Slow Clock Register
  [31] HDMI_DDC_CLK_GATING — 0: Clock is OFF 1: Clock is ON. SCLK = OSC24M.
    0=OFF (Clock is OFF); 1=ON (Clock is ON. SCLK = OSC24M.)
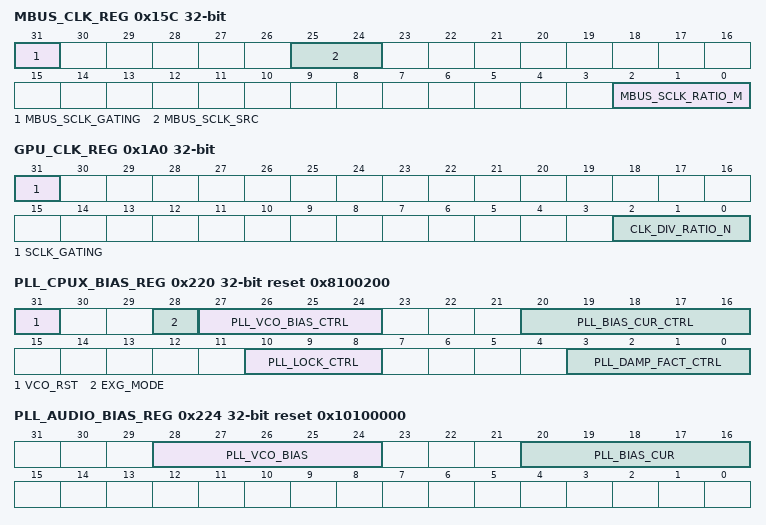
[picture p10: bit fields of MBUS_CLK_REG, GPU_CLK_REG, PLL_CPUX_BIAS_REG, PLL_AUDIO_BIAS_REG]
0x15C MBUS_CLK_REG — MBUS Clock Register
  [31] MBUS_SCLK_GATING — Gating Clock for MBUS 0: Clock is OFF 1: Clock is ON. MBUS_CLOCK = Clock Source/Divider M
    0=OFF (Clock is OFF); 1=ON (Clock is ON. MBUS_CLOCK = Clock Source/Divider M)
  [25:24] MBUS_SCLK_SRC — Clock Source Select 00: OSC24M 01: PLL_PERIPH0(2X) 10: PLL_DDR 11: /.
    0=OSC24M; 1=PLL_PERIPH0_openingparen_2X_closingparen_ (PLL_PERIPH0(2X)); 2=PLL_DDR; 3=_slash_
  [2:0] MBUS_SCLK_RATIO_M — Clock Divide Ratio (m) The pre-divided clock is divided by (m+1). The divider M is from 1 to 8. Note: If the clock has been changed ,it must wait for at least 16 cycles.
0x1A0 GPU_CLK_REG — GPU Clock Register
  [31] SCLK_GATING — 0: Clock is OFF 1: Clock is ON. SCLK= PLL-GPU/Divider N.
    0=OFF (Clock is OFF); 1=ON (Clock is ON. SCLK= PLL-GPU/Divider N.)
  [2:0] CLK_DIV_RATIO_N — Clock Pre Divide Ratio (N) The select clock source is pre-divided by( n+1). The divider N is from 1 to 8.
0x200 PLL_STABLE_TIME_REG0 reset 0xFF — PLL Stable Time Register 0
  [15:0] PLL_LOCK_TIME — PLL Lock Time (Unit: us). Note: When any PLL (except PLL_CPU) is enabled or changed, the corresponding PLL lock bit will be set after the PLL STABLE Time.
0x204 PLL_STABLE_TIME_REG1 reset 0xFF — PLL Stable Time Register 1
  [15:0] PLL_CPU_LOCK_TIME — PLL_CPU Lock Time (Unit: us). Note: When PLL_CPU is enabled or changed, the PLL_CPU lock bit will be set after the PLL_CPU STABLE Time.
0x220 PLL_CPUX_BIAS_REG reset 0x8100200 — PLL_CPUX Bias Register
  [31] VCO_RST — VCO reset in.
  [28] EXG_MODE — Exchange Mode. Note: CPU PLL source will select PLL_PERIPH0 instead of PLL_CPU
  [27:24] PLL_VCO_BIAS_CTRL — PLL VCO Bias Control[3:0].
  [20:16] PLL_BIAS_CUR_CTRL — PLL Bias Current Control[4:0].
  [10:8] PLL_LOCK_CTRL — PLL Lock Time Control[2:0].
  [3:0] PLL_DAMP_FACT_CTRL — PLL Damping Factor Control[3:0].
0x224 PLL_AUDIO_BIAS_REG reset 0x10100000 — PLL_AUDIO Bias Register
  [28:24] PLL_VCO_BIAS — PLL VCO Bias Current[4:0].
  [20:16] PLL_BIAS_CUR — PLL Bias Current[4:0].
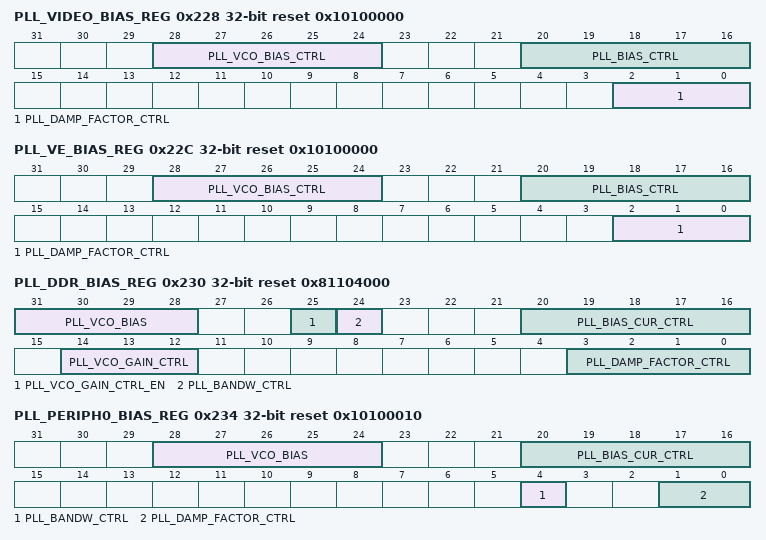
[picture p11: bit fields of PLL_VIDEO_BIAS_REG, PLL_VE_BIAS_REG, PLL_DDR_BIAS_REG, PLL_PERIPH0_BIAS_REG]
0x228 PLL_VIDEO_BIAS_REG reset 0x10100000 — PLL_VIDEO Bias Register
  [28:24] PLL_VCO_BIAS_CTRL — PLL VCO Bias Control[4:0].
  [20:16] PLL_BIAS_CTRL — PLL Bias Control[4:0].
  [2:0] PLL_DAMP_FACTOR_CTRL — PLL Damping Factor Control[2:0].
0x22C PLL_VE_BIAS_REG reset 0x10100000 — PLL_VE Bias Register
  fields as PLL_VIDEO_BIAS_REG
0x230 PLL_DDR_BIAS_REG reset 0x81104000 — PLL_DDR Bias Register
  [31:28] PLL_VCO_BIAS — PLL VCO Bias[3:0].
  [25] PLL_VCO_GAIN_CTRL_EN — PLL VCO Gain Control Enable. 0: Disable 1: Enable.
    0=Disable; 1=Enable
  [24] PLL_BANDW_CTRL — PLL Band Width Control. 0: Narrow 1: Wide.
    0=Narrow; 1=Wide
  [20:16] PLL_BIAS_CUR_CTRL — PLL Bias Current Control.
  [14:12] PLL_VCO_GAIN_CTRL — PLL VCO Gain Control Bit[2:0].
  [3:0] PLL_DAMP_FACTOR_CTRL — PLL Damping Factor Control[3:0].
0x234 PLL_PERIPH0_BIAS_REG reset 0x10100010 — PLL_PERIPH0 Bias Register
  [28:24] PLL_VCO_BIAS — PLL VCO Bias[4:0].
  [20:16] PLL_BIAS_CUR_CTRL — PLL Bias Current Control.
  [4] PLL_BANDW_CTRL — PLL Band Width Control. 0: Narrow 1: Wide
    0=Narrow; 1=Wide
  [1:0] PLL_DAMP_FACTOR_CTRL — PLL Damping Factor Control[1:0].
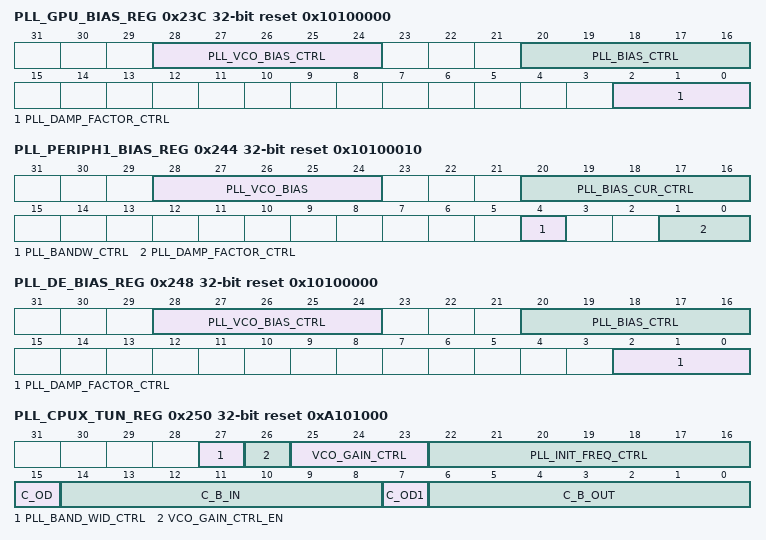
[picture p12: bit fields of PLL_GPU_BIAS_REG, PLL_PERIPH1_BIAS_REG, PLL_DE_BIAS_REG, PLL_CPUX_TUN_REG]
0x23C PLL_GPU_BIAS_REG reset 0x10100000 — PLL_GPU Bias Register
  fields as PLL_VIDEO_BIAS_REG
0x244 PLL_PERIPH1_BIAS_REG reset 0x10100010 — PLL_PERIPH1 Bias Register
  fields as PLL_PERIPH0_BIAS_REG
0x248 PLL_DE_BIAS_REG reset 0x10100000 — PLL_DE Bias Register
  fields as PLL_VIDEO_BIAS_REG
0x250 PLL_CPUX_TUN_REG reset 0xA101000 — PLL_CPUX Tuning Register
  [27] PLL_BAND_WID_CTRL — PLL Band Width Control. 0: Narrow 1: Wide
    0=Narrow; 1=Wide
  [26] VCO_GAIN_CTRL_EN — VCO Gain Control Enable. 0: Disable 1: Enable
    0=Disable; 1=Enable
  [25:23] VCO_GAIN_CTRL — VCO Gain Control Bits[2:0].
  [22:16] PLL_INIT_FREQ_CTRL — PLL Initial Frequency Control[6:0].
  [15] C_OD — C-Reg-Od For Verify.
  [14:8] C_B_IN — C-B-In[6:0] For Verify.
  [7] C_OD1 — C-Reg-Od1 For Verify.
  [6:0] C_B_OUT ro — C-B-Out[6:0] For Verify.
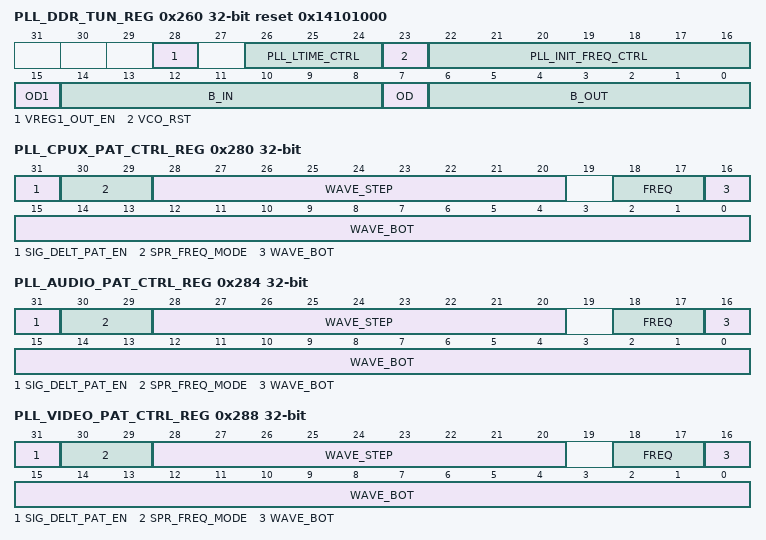
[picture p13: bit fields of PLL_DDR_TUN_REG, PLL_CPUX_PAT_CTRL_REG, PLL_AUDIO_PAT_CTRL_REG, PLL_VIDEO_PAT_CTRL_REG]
0x260 PLL_DDR_TUN_REG reset 0x14101000 — PLL_DDR Tuning Register
  [28] VREG1_OUT_EN — Vreg1 Out Enable. 0: Disable 1: Enable
    0=Disable; 1=Enable
  [26:24] PLL_LTIME_CTRL — PLL Lock Time Control[2:0].
  [23] VCO_RST — VCO Reset In.
  [22:16] PLL_INIT_FREQ_CTRL — PLL Initial Frequency Control[6:0].
  [15] OD1 — Reg-Od1 For Verify.
  [14:8] B_IN — B-In[6:0] For Verify.
  [7] OD — Reg-Od For Verify.
  [6:0] B_OUT ro — B-Out[6:0] For Verify.
0x280 PLL_CPUX_PAT_CTRL_REG — PLL_CPUX Pattern Control Register
  [31] SIG_DELT_PAT_EN — Sigma-delta Pattern Enable.
  [30:29] SPR_FREQ_MODE — Spread Frequency Mode. 00: DC=0 01: DC=1 1X: Triangular
    0=DC_equals_0 (DC=0); 1=DC_equals_1 (DC=1); 2=Triangular
  [28:20] WAVE_STEP
  [18:17] FREQ — Frequency. 00: 31.5KHz 01: 32KHz 10: 32.5KHz 11: 33KHz
    0=_31_point_5KHz (31.5KHz); 1=_32KHz; 2=_32_point_5KHz (32.5KHz); 3=_33KHz
  [16:0] WAVE_BOT — Wave Bottom.
0x284 PLL_AUDIO_PAT_CTRL_REG
  fields as PLL_CPUX_PAT_CTRL_REG
0x288 PLL_VIDEO_PAT_CTRL_REG
  fields as PLL_CPUX_PAT_CTRL_REG
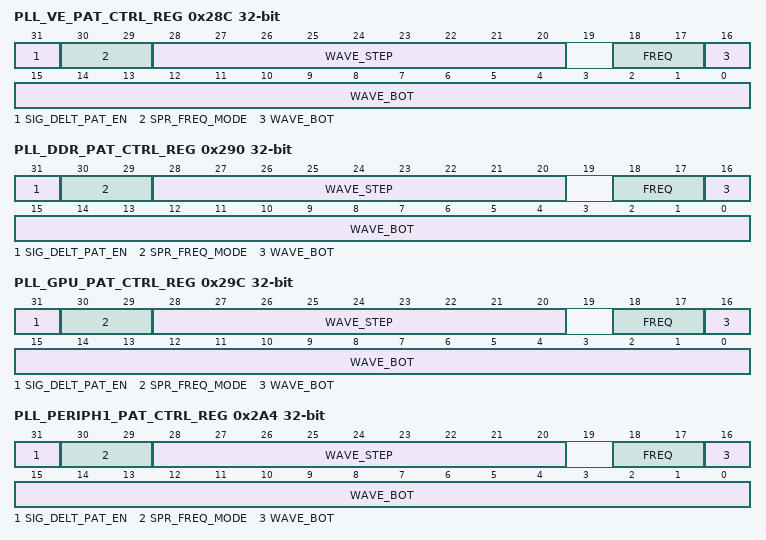
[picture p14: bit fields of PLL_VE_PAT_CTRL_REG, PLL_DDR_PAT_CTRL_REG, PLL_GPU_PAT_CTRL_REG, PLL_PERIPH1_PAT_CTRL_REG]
0x28C PLL_VE_PAT_CTRL_REG — PLL_VE Pattern Control Register
  fields as PLL_CPUX_PAT_CTRL_REG
0x290 PLL_DDR_PAT_CTRL_REG
  fields as PLL_CPUX_PAT_CTRL_REG
0x29C PLL_GPU_PAT_CTRL_REG — PLL_GPU Pattern Control Register
  [31] SIG_DELT_PAT_EN — Sigma-Delta Pattern Enable.
  [30:29] SPR_FREQ_MODE — Spread Frequency Mode. 00: DC=0 01: DC=1 1X: Triangular
    0=DC_equals_0 (DC=0); 1=DC_equals_1 (DC=1); 2=Triangular
  [28:20] WAVE_STEP
  [18:17] FREQ — Frequency. 00: 31.5KHz 01: 32KHz 10: 32.5KHz 11: 33KHz
    values as PLL_CPUX_PAT_CTRL_REG.FREQ
  [16:0] WAVE_BOT — Wave Bottom.
0x2A4 PLL_PERIPH1_PAT_CTRL_REG
  fields as PLL_GPU_PAT_CTRL_REG
0x2A8 PLL_DE_PAT_CTRL_REG — PLL_DE Pattern Control Register
  fields as PLL_GPU_PAT_CTRL_REG
0x2C0 BUS_SOFT_RST_REG0 — Bus Software Reset Register 0
  [all] fields
    0=Assert; 1=deassert
  [31] USBOHCI3_RST — USBOHCI3_RST. USB OHCI3 Reset Control 0: Assert 1: De-assert
  [30] USBOHCI2_RST — USBOHCI2_RST. USB OHCI2 Reset Control 0: Assert 1: De-assert
  [29] USBOHCI1_RST — USBOHCI1_RST. USB OHCI1 Reset Control 0: Assert 1: De-assert
  [28] USB_OTG_OHCI0_RST — USB OTG_OHCI0_RST. USB OTG_OHCI0 Reset Control 0: Assert 1: De-assert
  [27] USBEHCI3_RST — USBEHCI3_RST. USB EHCI3 Reset Control 0: Assert 1: De-assert
  [26] USBEHCI2_RST — USBEHCI2_RST. USB EHCI2 Reset Control 0: Assert 1: De-assert
  [25] USBEHCI1_RST — USBEHCI1_RST. USB EHCI1 Reset Control 0: Assert 1: De-assert.
  [24] USB_OTG_EHCI0_RST — USB OTG_EHCI0_RST. USB OTG_EHCI0 Reset Control 0: Assert 1: De-assert
  [23] USB_OTG_DEVICE_RST — USB OTG_Device_RST. USB OTG_Device Reset Control 0: Assert 1: De-assert
  [21] SPI1_RST — SPI1_RST. SPI1 Reset. 0: Assert 1: De-assert
  [20] SPI0_RST — SPI0_RST. SPI0 Reset. 0: Assert 1: De-assert
  [19] HSTMR_RST — HSTMR_RST. HSTMR Reset. 0: Assert 1: De-assert
  [18] TS_RST — TS_RST. TS Reset. 0: Assert 1: De-assert
  [17] EMAC_RST — EMAC_RST. EMAC Reset. 0: Assert 1: De-assert
  [14] SDRAM_RST — SDRAM_RST. SDRAM AHB Reset. 0: Assert 1: De-assert
  [13] NAND_RST — NAND_RST. NAND Reset. 0: Assert 1: De-assert
  [10] SD2_RST — SD2_RST. SD/MMC2 Reset. 0: Assert 1: De-assert
  [9] SD1_RST — SD1_RST. SD/MMC1 Reset. 0: Assert 1: De-assert
  [8] SD0_RST — SD0_RST. SD/MMC0 Reset. 0: Assert 1: De-assert
  [6] DMA_RST — DMA_RST. DMA Reset. 0: Assert 1: De-assert
  [5] CE_RST — CE_RST. CE Reset. 0: Assert 1: De-assert
0x2C4 BUS_SOFT_RST_REG1 — Bus Software Reset Register 1
  [31] DBGSYS_RST — DBGSYS Reset. 0: Assert 1: De-assert
    0=Assert; 1=deassert
  [22] SPINLOCK_RST — SPINLOCK Reset. 0: Assert 1: De-assert.
    0=Assert; 1=deassert
  [21] MSGBOX_RST — MSGBOX Reset. 0: Assert 1: De-assert.
    0=Assert; 1=deassert
  [20] GPU_RST — GPU Reset. 0: Assert 1: De-assert.
    0=Assert; 1=deassert
  [12] DE_RST — DE Reset. 0: Assert 1: De-assert.
    0=Assert; 1=deassert
  [11] HDMI1_RST — HDMI1 Reset. 0: Assert 1: De-assert.
    0=Assert; 1=deassert
  [10] HDMI0_RST — HDMI0 Reset. 0: Assert 1: De-assert.
    0=Assert; 1=deassert
  [9] TVE_RST — TVE Reset. 0: Assert 1: De-assert
    0=Assert; 1=deassert
  [8] CSI_RST — CSI Reset. 0: Assert 1: De-assert.
    0=Assert; 1=deassert
  [5] DEINTERLACE_RST — DEINTERLACE Reset. 0: Assert 1:De-assert
    0=Assert 1:De-assert
  [4] TCON1_RST — TCON1 Reset. 0: Assert 1: De-assert.
    0=Assert; 1=deassert
  [3] TCON0_RST — TCON0 Reset. 0: Assert 1: De-assert.
    0=Assert; 1=deassert
  [0] VE_RST — VE Reset. 0: Assert 1: De-assert.
    0=Assert; 1=deassert
0x2C8 BUS_SOFT_RST_REG2 — Bus Software Reset Register 2
  [2] EPHY_RST — EPHY Reset. 0: Assert 1: De-assert
    0=Assert; 1=deassert
0x2D0 BUS_SOFT_RST_REG3 — Bus Software Reset Register 3
  [all] fields
    0=Assert; 1=deassert
  [14] I2S_PCM_2_RST — I2S_PCM_2 Reset. 0: Assert 1: De-assert.
  [13] I2S_PCM_1_RST — I2S_PCM_1 Reset. 0: Assert 1: De-assert.
  [12] I2S_PCM_0_RST — I2S_PCM_0 Reset. 0: Assert 1: De-assert.
  [8] THS_RST — THS Reset. 0: Assert 1: De-assert
  [1] OWA_RST — OWA Reset. 0: Assert 1: De-assert
  [0] AC_RST — AC Reset. 0: Assert 1: De-assert
0x2D8 BUS_SOFT_RST_REG4 — Bus Software Reset Register 4
  [all] fields
    0=Assert; 1=deassert
  [20] SCR_RST — SCR Reset. 0: Assert 1: De-assert
  [n+16] UART{n}_RST (n=0..3) — UART{n} Reset. 0: Assert 1: De-assert.
  [2] TWI2_RST — TWI2 Reset. 0: Assert 1: De-assert.
  [1] TWI1_RST — TWI1 Reset. 0: Assert 1: De-assert.
  [0] TWI0_RST — TWI0 Reset. 0: Assert 1: De-assert.
0x2F0 CCU_SEC_SWITCH_REG — CCU Security Switch Register
  [2] MBUS_SEC — MBUS clock register security 0:Secure 1:Non-secure Including MBUS Reset Register and MBUS Clock Register
  [1] BUS_SEC — Bus relevant registers` security 0:Secure 1:Non-secure Including AXI/AHB/APB relevant registers,such as CPUX/AXI Configuration Register,AHB1/APB1 Configuration Register,APB2 Configuration Register, AHB2 Configuration Register.
  [0] PLL_SEC — PLL relevant registers` security. 0:Secure 1:Non-secure Including PLL_CPUX Control Register,PLL_AUDIO Control Register,PLL_VIDEO Control Register,PLL_VE Control Register,PLL_DDR Control Register,PLL_ PEPIPH0 Control Register,PLL_GPU Control Register,PLL_PERIPH1 Control Register,PLL_DE Control Register and offset from 0x200 to 0x2A8 relevant registers.
0x300 PS_CTRL_REG — PS Control Register
  [7] DET_FIN — Detect Finish. 0: Unfinished 1: Finished Set 1 to this bit will clear it.
    0=Unfinished; 1=Finished Set 1 to this bit will clear it
  [6] DLY_SEL — Delay Select 0: 1 Cycle 1: 2 Cycles
    0=_1_Cycle; 1=2 Cycles
  [5:4] OSC_SEL — OSC Select. 00: IDLE 01: SVT 10: LVT 11: ULVT
    0=IDLE; 1=SVT; 2=LVT; 3=ULVT
  [3:1] TIME_DET — Time detect. 000: 0.5/4 us 001: 0.5/2 us 002: 0.5/1 us 003: 0.5*2us ........... 111:0.5*2^5us
    0=_0_point_5_slash_4 (0.5/4 us); 1=_0_point_5_slash_2 (0.5/2 us); 2=_0_point_5_slash_1 (0.5/1 us); 3=_0_point_5_times_2us (0.5*2us ........... 111:0.5*2^5us)
  [0] MOD_EN — Module enable. 0: Disable 1: Enable
    0=Disable; 1=Enable
0x304 PS_CNT_REG — PS Counter Register
  [15:0] PS_CNT — PS Counter.
